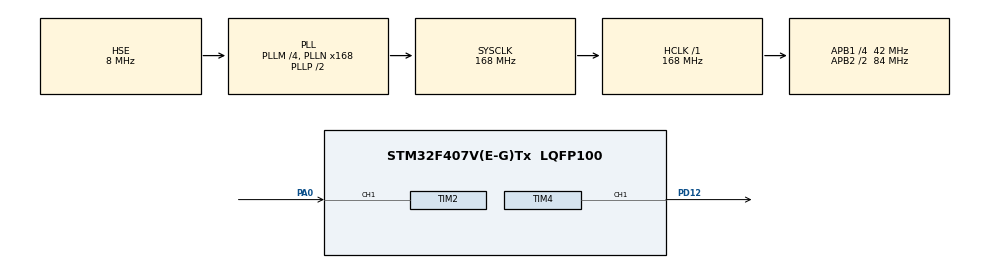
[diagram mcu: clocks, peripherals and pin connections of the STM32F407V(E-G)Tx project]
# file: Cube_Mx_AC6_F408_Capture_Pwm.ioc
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Mcu.Family=STM32F4
Mcu.Name=STM32F407V(E-G)Tx
Mcu.Package=LQFP100
NVIC.PriorityGroup=NVIC_PRIORITYGROUP_4
NVIC.TIM2_IRQn=true\:0\:0\:false\:false\:true
PA0-WKUP.Signal=S_TIM2_CH1_ETR
PD12.Signal=S_TIM4_CH1
PH0-OSC_IN.Mode=HSE-External-Oscillator
PH0-OSC_IN.Signal=RCC_OSC_IN
PH1-OSC_OUT.Mode=HSE-External-Oscillator
PH1-OSC_OUT.Signal=RCC_OSC_OUT
ProjectManager.HeapSize=0x200
ProjectManager.StackSize=0x400
ProjectManager.TargetToolchain=SW4STM32
RCC.48MHZClocksFreq_Value=84000000
RCC.AHBFreq_Value=168000000
RCC.APB1CLKDivider=RCC_HCLK_DIV4
RCC.APB1Freq_Value=42000000
RCC.APB1TimFreq_Value=84000000
RCC.APB2CLKDivider=RCC_HCLK_DIV2
RCC.APB2Freq_Value=84000000
RCC.APB2TimFreq_Value=168000000
RCC.CortexFreq_Value=168000000
RCC.HCLKFreq_Value=168000000
RCC.HSE_VALUE=8000000
RCC.HSI_VALUE=16000000
RCC.LSE_VALUE=32768
RCC.PLLM=4
RCC.PLLN=168
RCC.PLLSourceVirtual=RCC_PLLSOURCE_HSE
RCC.SYSCLKFreq_VALUE=168000000
RCC.SYSCLKSource=RCC_SYSCLKSOURCE_PLLCLK
RCC.VCOOutputFreq_Value=336000000
SH.S_TIM2_CH1_ETR.0=TIM2_CH1,Input_Capture1_from_TI1
SH.S_TIM4_CH1.0=TIM4_CH1,PWM Generation1 CH1
TIM2.ICFilter_CH1=15
TIM2.Period=50000
TIM2.Prescaler=83
TIM4.Period=41999
TIM4.Prescaler=39
TIM4.Pulse-PWM\ Generation1\ CH1=21000
board=Cube_Mx_AC6_F408_Capture_Pwm

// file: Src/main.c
/**
  ******************************************************************************
  * File Name          : main.c
  * Description        : Main program body
  ******************************************************************************
  *
  * COPYRIGHT(c) 2017 STMicroelectronics
  *
  * Redistribution and use in source and binary forms, with or without modification,
  * are permitted provided that the following conditions are met:
  *   1. Redistributions of source code must retain the above copyright notice,
  *      this list of conditions and the following disclaimer.
  *   2. Redistributions in binary form must reproduce the above copyright notice,
  *      this list of conditions and the following disclaimer in the documentation
  *      and/or other materials provided with the distribution.
  *   3. Neither the name of STMicroelectronics nor the names of its contributors
  *      may be used to endorse or promote products derived from this software
  *      without specific prior written permission.
  *
  * THIS SOFTWARE IS PROVIDED BY THE COPYRIGHT HOLDERS AND CONTRIBUTORS "AS IS"
  * AND ANY EXPRESS OR IMPLIED WARRANTIES, INCLUDING, BUT NOT LIMITED TO, THE
  * IMPLIED WARRANTIES OF MERCHANTABILITY AND FITNESS FOR A PARTICULAR PURPOSE ARE
  * DISCLAIMED. IN NO EVENT SHALL THE COPYRIGHT HOLDER OR CONTRIBUTORS BE LIABLE
  * FOR ANY DIRECT, INDIRECT, INCIDENTAL, SPECIAL, EXEMPLARY, OR CONSEQUENTIAL
  * DAMAGES (INCLUDING, BUT NOT LIMITED TO, PROCUREMENT OF SUBSTITUTE GOODS OR
  * SERVICES; LOSS OF USE, DATA, OR PROFITS; OR BUSINESS INTERRUPTION) HOWEVER
  * CAUSED AND ON ANY THEORY OF LIABILITY, WHETHER IN CONTRACT, STRICT LIABILITY,
  * OR TORT (INCLUDING NEGLIGENCE OR OTHERWISE) ARISING IN ANY WAY OUT OF THE USE
  * OF THIS SOFTWARE, EVEN IF ADVISED OF THE POSSIBILITY OF SUCH DAMAGE.
  *
  ******************************************************************************
  */
#include "main.h"
#include "stm32f4xx_hal.h"

TIM_HandleTypeDef htim2;
TIM_HandleTypeDef htim4;

/* USER CODE BEGIN PV */
/* Private variables ---------------------------------------------------------*/
long counter,IC_Value;

/* USER CODE END PV */

void SystemClock_Config(void);
void Error_Handler(void);
static void MX_GPIO_Init(void);
static void MX_TIM4_Init(void);
static void MX_TIM2_Init(void);

void HAL_TIM_MspPostInit(TIM_HandleTypeDef *htim);

/* USER CODE BEGIN PFP */
/* Private function prototypes -----------------------------------------------*/

/* USER CODE END PFP */

int main(void)
{

  /* MCU Configuration----------------------------------------------------------*/

  /* Reset of all peripherals, Initializes the Flash interface and the Systick. */
  HAL_Init();

  /* Configure the system clock */
  SystemClock_Config();

  /* Initialize all configured peripherals */
  MX_GPIO_Init();
  MX_TIM4_Init();
  MX_TIM2_Init();

  /* USER CODE BEGIN 2 */
  HAL_TIM_PWM_Start(&htim4,TIM_CHANNEL_1);
  HAL_TIM_IC_Start_IT(&htim2,TIM_CHANNEL_1);
  /* USER CODE END 2 */

  /* Infinite loop */
  /* USER CODE BEGIN WHILE */
  while (1)
  {
	  counter=__HAL_TIM_GetCounter(&htim2);

  /* USER CODE END WHILE */

  }

}

/** System Clock Configuration
*/
void SystemClock_Config(void)
{

  RCC_OscInitTypeDef RCC_OscInitStruct;
  RCC_ClkInitTypeDef RCC_ClkInitStruct;

    /**Configure the main internal regulator output voltage
    */
  __HAL_RCC_PWR_CLK_ENABLE();

  __HAL_PWR_VOLTAGESCALING_CONFIG(PWR_REGULATOR_VOLTAGE_SCALE1);

    /**Initializes the CPU, AHB and APB busses clocks
    */
  RCC_OscInitStruct.OscillatorType = RCC_OSCILLATORTYPE_HSE;
  RCC_OscInitStruct.HSEState = RCC_HSE_ON;
  RCC_OscInitStruct.PLL.PLLState = RCC_PLL_ON;
  RCC_OscInitStruct.PLL.PLLSource = RCC_PLLSOURCE_HSE;
  RCC_OscInitStruct.PLL.PLLM = 4;
  RCC_OscInitStruct.PLL.PLLN = 168;
  RCC_OscInitStruct.PLL.PLLP = RCC_PLLP_DIV2;
  RCC_OscInitStruct.PLL.PLLQ = 4;
  if (HAL_RCC_OscConfig(&RCC_OscInitStruct) != HAL_OK)
  {
    Error_Handler();
  }

    /**Initializes the CPU, AHB and APB busses clocks
    */
  RCC_ClkInitStruct.ClockType = RCC_CLOCKTYPE_HCLK|RCC_CLOCKTYPE_SYSCLK
                              |RCC_CLOCKTYPE_PCLK1|RCC_CLOCKTYPE_PCLK2;
  RCC_ClkInitStruct.SYSCLKSource = RCC_SYSCLKSOURCE_PLLCLK;
  RCC_ClkInitStruct.AHBCLKDivider = RCC_SYSCLK_DIV1;
  RCC_ClkInitStruct.APB1CLKDivider = RCC_HCLK_DIV4;
  RCC_ClkInitStruct.APB2CLKDivider = RCC_HCLK_DIV2;

  if (HAL_RCC_ClockConfig(&RCC_ClkInitStruct, FLASH_LATENCY_5) != HAL_OK)
  {
    Error_Handler();
  }

    /**Configure the Systick interrupt time
    */
  HAL_SYSTICK_Config(HAL_RCC_GetHCLKFreq()/1000);

    /**Configure the Systick
    */
  HAL_SYSTICK_CLKSourceConfig(SYSTICK_CLKSOURCE_HCLK);

  /* SysTick_IRQn interrupt configuration */
  HAL_NVIC_SetPriority(SysTick_IRQn, 0, 0);
}

/* TIM2 init function */
static void MX_TIM2_Init(void)
{

  TIM_MasterConfigTypeDef sMasterConfig;
  TIM_IC_InitTypeDef sConfigIC;

  htim2.Instance = TIM2;
  htim2.Init.Prescaler = 83;
  htim2.Init.CounterMode = TIM_COUNTERMODE_UP;
  htim2.Init.Period = 50000;
  htim2.Init.ClockDivision = TIM_CLOCKDIVISION_DIV1;
  if (HAL_TIM_IC_Init(&htim2) != HAL_OK)
  {
    Error_Handler();
  }

  sMasterConfig.MasterOutputTrigger = TIM_TRGO_RESET;
  sMasterConfig.MasterSlaveMode = TIM_MASTERSLAVEMODE_DISABLE;
  if (HAL_TIMEx_MasterConfigSynchronization(&htim2, &sMasterConfig) != HAL_OK)
  {
    Error_Handler();
  }

  sConfigIC.ICPolarity = TIM_INPUTCHANNELPOLARITY_BOTHEDGE;
  sConfigIC.ICSelection = TIM_ICSELECTION_DIRECTTI;
  sConfigIC.ICPrescaler = TIM_ICPSC_DIV1;
  sConfigIC.ICFilter = 15;
  if (HAL_TIM_IC_ConfigChannel(&htim2, &sConfigIC, TIM_CHANNEL_1) != HAL_OK)
  {
    Error_Handler();
  }

}

/* TIM4 init function */
static void MX_TIM4_Init(void)
{

  TIM_MasterConfigTypeDef sMasterConfig;
  TIM_OC_InitTypeDef sConfigOC;

  htim4.Instance = TIM4;
  htim4.Init.Prescaler = 0;
  htim4.Init.CounterMode = TIM_COUNTERMODE_UP;
  htim4.Init.Period = 20999;
  htim4.Init.ClockDivision = TIM_CLOCKDIVISION_DIV1;
  if (HAL_TIM_PWM_Init(&htim4) != HAL_OK)
  {
    Error_Handler();
  }

  sMasterConfig.MasterOutputTrigger = TIM_TRGO_RESET;
  sMasterConfig.MasterSlaveMode = TIM_MASTERSLAVEMODE_DISABLE;
  if (HAL_TIMEx_MasterConfigSynchronization(&htim4, &sMasterConfig) != HAL_OK)
  {
    Error_Handler();
  }

  sConfigOC.OCMode = TIM_OCMODE_PWM1;
  sConfigOC.Pulse = 1000;
  sConfigOC.OCPolarity = TIM_OCPOLARITY_HIGH;
  sConfigOC.OCFastMode = TIM_OCFAST_DISABLE;
  if (HAL_TIM_PWM_ConfigChannel(&htim4, &sConfigOC, TIM_CHANNEL_1) != HAL_OK)
  {
    Error_Handler();
  }

  HAL_TIM_MspPostInit(&htim4);

}

/** Configure pins as
        * Analog
        * Input
        * Output
        * EVENT_OUT
        * EXTI
*/
static void MX_GPIO_Init(void)
{

  /* GPIO Ports Clock Enable */
  __HAL_RCC_GPIOH_CLK_ENABLE();
  __HAL_RCC_GPIOA_CLK_ENABLE();
  __HAL_RCC_GPIOD_CLK_ENABLE();

}

/* USER CODE BEGIN 4 */
void HAL_TIM_IC_CaptureCallback(TIM_HandleTypeDef *htim){
	if (htim->Instance==TIM2){
		IC_Value=__HAL_TIM_GetCompare(&htim2,TIM_CHANNEL_1);
		__HAL_TIM_SetCounter(&htim2,0);
	}

}
/* USER CODE END 4 */

void Error_Handler(void)
{
  while(1)
  {
  }
}

/************************ (C) COPYRIGHT STMicroelectronics *****END OF FILE****/
